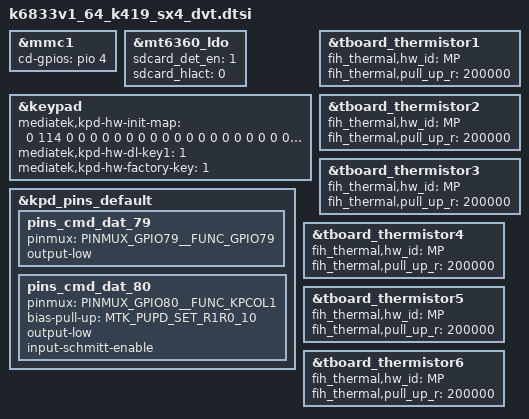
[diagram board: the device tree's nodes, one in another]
/* OVERLAY,SX4,DVT */
#include "overlay_sx4_dvt_fih_info.dtsi"
#include "overlay_sx3_pre_evt_fih_fp.dtsi"
#include <dt-bindings/gpio/gpio.h>


/* SD card insert detect high active change */
&mmc1 {
	cd-gpios = <&pio 4 GPIO_ACTIVE_HIGH>;
};

&mt6360_ldo {
	sdcard_det_en = <1>;
	sdcard_hlact = <0>;
};

&keypad {
	/delete-property/ mediatek,kpd-hw-init-map;
	/delete-property/ mediatek,kpd-hw-dl-key1;
	/delete-property/ mediatek,kpd-hw-factory-key;
	mediatek,kpd-hw-init-map = <0 114 0 0 0 0 0 0 0 0 0 0 0 0 0 0 0 0 0 0 0 0 0 0 0 0 0 0 0 0 0 0 0 0 0 0 0 0 0 0 0 0 0 0 0 0 0 0 0 0 0 0 0 0 0 0 0 0 0 0 0 0 0 0 0 0 0 0 0 0 0 0 >;
	mediatek,kpd-hw-dl-key1 = <1>;
	mediatek,kpd-hw-factory-key = <1>;
};

&kpd_pins_default {
	/delete-node/ pins_cmd_dat;
	pins_cmd_dat_79 {
		pinmux = <PINMUX_GPIO79__FUNC_GPIO79>;
		output-low;
	};
	pins_cmd_dat_80 {
		pinmux = <PINMUX_GPIO80__FUNC_KPCOL1>;
		bias-pull-up = <MTK_PUPD_SET_R1R0_10>;
		output-low;
		input-schmitt-enable;
	};
};

&tboard_thermistor1 {
	fih_thermal,hw_id = "MP";
	fih_thermal,pull_up_r = <200000>;
};

&tboard_thermistor2 {
	fih_thermal,hw_id = "MP";
	fih_thermal,pull_up_r = <200000>;
};

&tboard_thermistor3 {
	fih_thermal,hw_id = "MP";
	fih_thermal,pull_up_r = <200000>;
};

&tboard_thermistor4 {
	fih_thermal,hw_id = "MP";
	fih_thermal,pull_up_r = <200000>;
};
&tboard_thermistor5 {
	fih_thermal,hw_id = "MP";
	fih_thermal,pull_up_r = <200000>;
};

&tboard_thermistor6 {
	fih_thermal,hw_id = "MP";
	fih_thermal,pull_up_r = <200000>;
};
